# I94100_v1_3 register map
File version: 1.0
Registers are 32-bit, read-write, reset 0x0 unless marked. A register's access mark holds for its fields unless they carry their own. Offsets are from the block's base; [hi:lo] are bit positions; lines under a group give offsets from that group; {n}, {i} and the like mark numbered series; 'fields as' and 'values as' point back to an identical list.

## CLK — CLK Register Map
Base 0x40000200
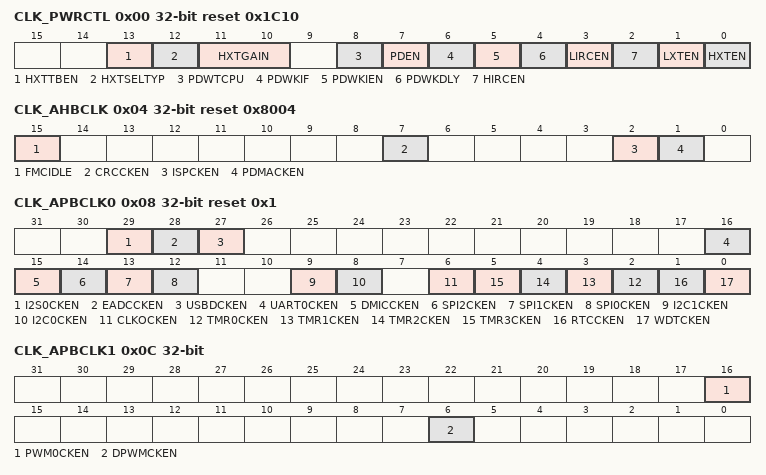
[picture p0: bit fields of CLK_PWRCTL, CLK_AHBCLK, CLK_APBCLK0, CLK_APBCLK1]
0x00 CLK_PWRCTL reset 0x1C10 (reset mask 0xFFFFFFF0) — System Power-down Control Register
  [13] HXTTBEN — HXT Crystal TURBO Mode (Write Protected). This is a protected register. Please refer to open lock sequence to program it.
    0=HXT Crystal TURBO mode disabled; 1=HXT Crystal TURBO mode enabled
  [12] HXTSELTYP — HXT Crystal Type Select Bit (Write Protected). This is a protected register. Please refer to open lock sequence to program it. Note: This bit is write protected. Refer to the SYS_REGLCTL register.
    0=Select INV type; 1=Select GM type
  [11:10] HXTGAIN — HXT Gain Control Bit (Write Protected). This is a protected register. Please refer to open lock sequence to program it. Gain control is used to enlarge the gain of crystal to make sure crystal work normally. If gain control is enabled, crystal will consume more power than gain control off. Note: This bit is write protected. Refer to the SYS_REGLCTL register.
    0=HXT frequency is lower than from 8 MHz; 1=HXT frequency is from 8 MHz to 12 MHz; 2=HXT frequency is from 12 MHz to 16 MHz; 3=HXT frequency is higher than 16 MHz
  [8] PDWTCPU — this Bit Control the Power-down Entry Condition (Write Protected). Note: This bit is write protected. Refer to the SYS_REGLCTL register.
    1=Chip enters Power-down mode when the both PDWTCPU and PDEN bits are set to 1 and CPU runs WFI instruction
  [7] PDEN — System Power-down Enable (Write Protected). When this bit is set to 1, Power-down mode is enabled and chip keeps active till the CPU sleep mode is also active and then the chip enters Power-down mode. When chip wakes up from Power-down mode, this bit is auto cleared. Users need to set this bit again for next Power-down. In Power-down mode, HXT and the HIRC will be disabled in this mode, but LXT and LIRC are not controlled by Power-down mode. In Power-down mode, the PLL and system clock are disabled, and ignored the clock source selection. The clocks of peripheral are not controlled by Power-down mode, if the peripheral clock source is from LXT or LIRC. Note: This bit is write protected. Refer to the SYS_REGLCTL register.
    0=Chip will not enter Power-down mode after CPU sleep command WFI; 1=Chip enters Power-down mode after CPU sleep command WFI
  [6] PDWKIF — Power-down Mode Wake-up Interrupt Status. Set by "Power-down wake-up event", it indicates that resume from Power-down mode" The flag is set if any wake-up source is occurred. Refer Power Modes and Wake-up Sources chapter. Note1: Write 1 to clear the bit to 0. Note2: This bit works only if PDWKIEN (CLK_PWRCTL[5]) set to 1.
  [5] PDWKIEN — Power-down Mode Wake-up Interrupt Enable Bit (Write Protected). Note1: The interrupt will occur when both PDWKIF and PDWKIEN are high. Note2: This bit is write protected. Refer to the SYS_REGLCTL register.
    0=Power-down mode wake-up interrupt Disabled; 1=Power-down mode wake-up interrupt Enabled
  [4] PDWKDLY — Enable the Wake-up Delay Counter (Write Protected). When the chip wakes up from Power-down mode, the clock control will delay certain clock cycles to wait system clock stable. The delayed clock cycle is 4096 clock cycles when chip works at external high speed crystal oscillator (HXT), and 128 clock cycles when chip works at internal high speed RC oscillator (HIRC). Note: This bit is write protected. Refer to the SYS_REGLCTL register.
    0=Clock cycles delay Disabled; 1=Clock cycles delay Enabled
  [3] LIRCEN — LIRC Enable Bit (Write Protected). Note 1: This bit is write protected. Refer to the SYS_REGLCTL register. Note 2: The reset value of this bit is 1. Note 3: The value of this bit must be kept 1.
    0=Internal low speed RC oscillator (LIRC) Disabled; 1=Internal low speed RC oscillator (LIRC) Enabled
  [2] HIRCEN — HIRC Enable Bit (Write Protected). Note 1: This bit is write protected. Refer to the SYS_REGLCTL register. Note 2: The reset value of this bit is 1.
    0=Internal high speed RC oscillator (HIRC) Disabled; 1=Internal high speed RC oscillator (HIRC) Enabled
  [1] LXTEN — LXT Enable Bit (Write Protected). Note 1: This bit is write protected. Refer to the SYS_REGLCTL register. Note 2: The reset value of this bit is 0.
    0=External low speed crystal (LXT) Disabled; 1=External low speed crystal (LXT) Enabled
  [0] HXTEN — HXT Enable Bit (Write Protected). The bit default value is set by flash controller user configuration register CONFIG0 [26]. When the default clock source is from HXT, this bit is set to 1 automatically. Note: This bit is write protected. Refer to the SYS_REGLCTL register.
    0=External high speed crystal (HXT) Disabled; 1=External high speed crystal (HXT) Enabled
0x04 CLK_AHBCLK reset 0x8004 — AHB Devices Clock Enable Control Register
  [15] FMCIDLE — Flash Memory Controller Clock Enable Bit in IDLE Mode
    0=FMC clock Disabled when chip is under IDLE mode; 1=FMC clock Enabled when chip is under IDLE mode
  [7] CRCCKEN — CRC Generator Controller Clock Enable Bit
    0=CRC peripheral clock Disabled; 1=CRC peripheral clock Enabled
  [2] ISPCKEN — Flash ISP Controller Clock Enable Bit
    0=Flash ISP peripheral clock Disabled; 1=Flash ISP peripheral clock Enabled
  [1] PDMACKEN — PDMA Controller Clock Enable Bit
    0=PDMA peripheral clock Disabled; 1=PDMA peripheral clock Enabled
0x08 CLK_APBCLK0 reset 0x1 — APB Devices Clock Enable Control Register 0
  [29] I2S0CKEN — I2S0 Clock Enable Bit
    0=I2S0 Clock Disabled; 1=I2S0 Clock Enabled
  [28] EADCCKEN — Enhanced Analog-digital-converter (EADC) Clock Enable Bit
    0=EADC clock Disabled; 1=EADC clock Enabled
  [27] USBDCKEN — USB Device Clock Enable Bit
    0=USB Device clock Disabled; 1=USB Device clock Enabled
  [16] UART0CKEN — UART0 Clock Enable Bit
    0=UART0 clock Disabled; 1=UART0 clock Enabled
  [15] DMICCKEN — DMIC Clock Enable Bit
    0=DMIC clock Disabled; 1=DMIC clock Enabled
  [14] SPI2CKEN — SPI2 Clock Enable Bit
    0=SPI2 clock Disabled; 1=SPI2 clock Enabled
  [13] SPI1CKEN — SPI1 Clock Enable Bit
    0=SPI1 clock Disabled; 1=SPI1 clock Enabled
  [12] SPI0CKEN — SPI0 Clock Enable Bit
    0=SPI0 clock Disabled; 1=SPI0 clock Enabled
  [9] I2C1CKEN — I2C1 Clock Enable Bit
    0=I2C1 clock Disabled; 1=I2C1 clock Enabled
  [8] I2C0CKEN — I2C0 Clock Enable Bit
    0=I2C0 clock Disabled; 1=I2C0 clock Enabled
  [6] CLKOCKEN — CLKO Clock Enable Bit
    0=CLKO clock Disabled; 1=CLKO clock Enabled
  [n+2] TMR{n}CKEN (n=0..3) — Timer{n} Clock Enable Bit
    0=Timer{n} clock Disabled; 1=Timer{n} clock Enabled
  [1] RTCCKEN — Real-time-clock APB Interface Clock Enable Bit. This bit is used to control the RTC APB clock only. The RTC peripheral clock source is selected from RTCSEL(CLK_CLKSEL3[8]). It can be selected to 32.768 kHz external low speed crystal or 10 kHz internal low speed RC oscillator (LIRC).
    0=RTC clock Disabled; 1=RTC clock Enabled
  [0] WDTCKEN — Watchdog Timer Clock Enable Bit (Write Protected). Note: This bit is write protected. Refer to the SYS_REGLCTL register.
    0=Watchdog timer clock Disabled; 1=Watchdog timer clock Enabled
0x0C CLK_APBCLK1 — APB Devices Clock Enable Control Register 1
  [16] PWM0CKEN — PWM0 Clock Enable Bit
    0=PWM0 clock Disabled; 1=PWM0 clock Enabled
  [6] DPWMCKEN — DPWM Clock Enable Bit
    0=DPWM clock Disabled; 1=DPWM clock Enabled
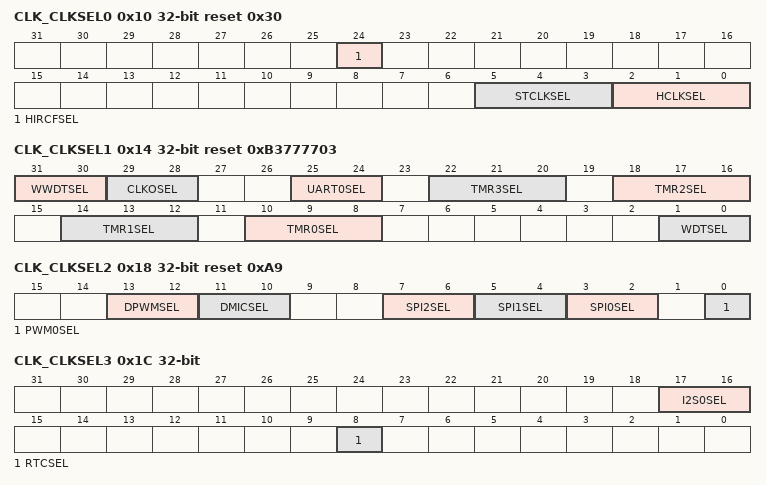
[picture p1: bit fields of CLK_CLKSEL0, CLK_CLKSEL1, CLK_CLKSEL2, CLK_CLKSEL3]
0x10 CLK_CLKSEL0 reset 0x30 (reset mask 0xFFFFFFF0) — Clock Source Select Control Register 0
  [24] HIRCFSEL — Internal High Speed RC Oscillator Frequency Selection. (Write Protect). Determines which trim setting to use for internal high speed RC oscillator. Note: This bit is write protected. Refer to the SYS_REGLCTL register.
    0=49.152 MHz; 1=48.0 MHz
  [5:3] STCLKSEL — Cortex®-M4 SysTick Clock Source Selection (Write Protected). Note2: The reset value of this field is 111b. Note3: This bit is write protected. Refer to the SYS_REGLCTL register.
    0=Clock source from HXT; 1=Clock source from LXT; 2=Clock source from HXT/2; 3=Clock source from HCLK/2; 7=Clock source from HIRC/2
  [2:0] HCLKSEL — HCLK Clock Source Selection (Write Protected). Before clock switching, the related clock sources (both pre-select and new-select) must be turned on and stable flag must be 1. The default value is reloaded from the value of CFOSC (CONFIG0[26]) in user configuration register of Flash controller by any reset. Therefore the default value is either 000b or 111b. Note: This bit is write protected. Refer to the SYS_REGLCTL register.
    0=Clock source from HXT; 1=Clock source from LXT; 2=Clock source from PLL; 3=Clock source from LIRC; 7=Clock source from HIRC
0x14 CLK_CLKSEL1 reset 0xB3777703 — Clock Source Select Control Register 1
  [31:30] WWDTSEL — Window Watchdog Timer Clock Source Selection
    2=Clock source from HCLK/2048; 3=Clock source from internal low speed RC oscillator (LIRC)
  [29:28] CLKOSEL — Clock Divider Clock Source Selection
    0=Clock source from external high speed crystal oscillator (HXT); 1=Clock source from external low speed crystal oscillator (LXT); 2=Clock source from HCLK; 3=Clock source from internal high speed RC oscillator (HIRC)
  [25:24] UART0SEL — UART0 Clock Source Selection
    0=Clock source from external high speed crystal oscillator (HXT); 1=Clock source from PLL; 2=Clock source from external low speed crystal oscillator (LXT); 3=Clock source from internal high speed RC oscillator (HIRC)
  [22:20] TMR3SEL — TIMER3 Clock Source Selection
    0=Clock source from external high speed crystal oscillator (HXT); 1=Clock source from external low speed crystal oscillator (LXT); 2=Clock source from PCLK1; 3=Clock source from external clock TM3 pin; 5=Clock source from internal low speed RC oscillator (LIRC); 7=Clock source from internal high speed RC oscillator (HIRC)
  [18:16] TMR2SEL — TIMER2 Clock Source Selection
    0=Clock source from external high speed crystal oscillator (HXT); 1=Clock source from external low speed crystal oscillator (LXT); 2=Clock source from PCLK1; 3=Clock source from external clock TM2 pin; 5=Clock source from internal low speed RC oscillator (LIRC); 7=Clock source from internal high speed RC oscillator (HIRC)
  [14:12] TMR1SEL — TIMER1 Clock Source Selection
    0=Clock source from external high speed crystal oscillator (HXT); 1=Clock source from external low speed crystal oscillator (LXT); 2=Clock source from PCLK0; 3=Clock source from external clock TM1 pin; 5=Clock source from internal low speed RC oscillator (LIRC); 7=Clock source from internal high speed RC oscillator (HIRC)
  [10:8] TMR0SEL — TIMER0 Clock Source Selection
    0=Clock source from external high speed crystal oscillator (HXT); 1=Clock source from external low speed crystal oscillator (LXT); 2=Clock source from PCLK0; 3=Clock source from external clock TM0 pin; 5=Clock source from internal low speed RC oscillator (LIRC); 7=Clock source from internal high speed RC oscillator (HIRC)
  [1:0] WDTSEL — Watchdog Timer Clock Source Selection (Write Protected). Note: This bit is write protected. Refer to the SYS_REGLCTL register.
    0=Reserved. Do not use; 1=Clock source from external low speed crystal oscillator (LXT); 2=Clock source from HCLK/2048; 3=Clock source from internal low speed RC oscillator (LIRC)
0x18 CLK_CLKSEL2 reset 0xA9 — Clock Source Select Control Register 2
  [13:12] DPWMSEL — DPWM Clock Source Selection
    0=Clock source from external high speed crystal oscillator (HXT); 1=Clock source from PLL; 2=Clock source from PCLK0; 3=Clock source from internal high speed RC oscillator (HIRC)
  [11:10] DMICSEL — DMIC Clock Source Selection
    0=Clock source from external high speed crystal oscillator (HXT); 1=Clock source from PLL; 2=Clock source from PCLK1; 3=Clock source from internal high speed RC oscillator (HIRC)
  [7:6] SPI2SEL — SPI2 Clock Source Selection
    values as DPWMSEL
  [5:4] SPI1SEL — SPI1 Clock Source Selection
    values as DMICSEL
  [3:2] SPI0SEL — SPI0 Clock Source Selection
    values as DPWMSEL
  [0] PWM0SEL — PWM0 Clock Source Selection. The peripheral clock source of PWM0 is defined by PWM0SEL.
    0=Clock source from PLL; 1=Clock source from PCLK0
0x1C CLK_CLKSEL3 — Clock Source Select Control Register 3
  [17:16] I2S0SEL — I2S0 Clock Source Selection
    0=Clock source from external high speed crystal oscillator (HXT); 1=Clock source from PLL clock; 2=Clock source from PCLK0; 3=Clock source from internal high speed RC oscillator (HIRC)
  [8] RTCSEL — RTC Clock Source Selection
    0=Clock source from external low speed crystal oscillator (LXT); 1=Clock source from internal low speed RC oscillator (LIRC)
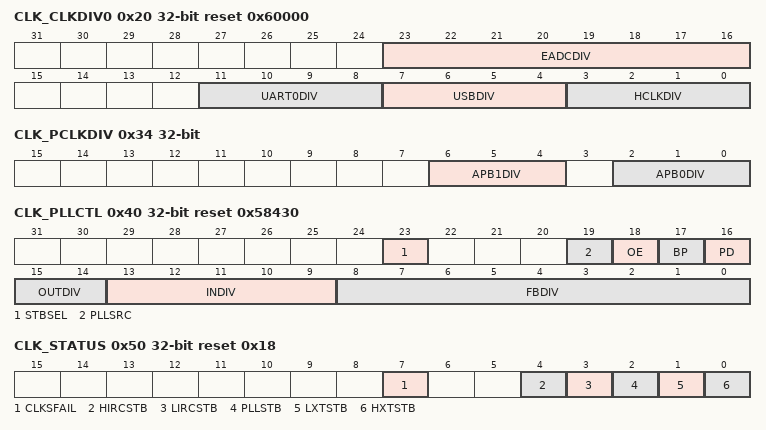
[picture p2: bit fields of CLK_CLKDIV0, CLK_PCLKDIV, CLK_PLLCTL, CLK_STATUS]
0x20 CLK_CLKDIV0 reset 0x60000 — Clock Divider Number Register 0
  [23:16] EADCDIV — EADC Clock Divide Number From EADC Clock Source
  [11:8] UART0DIV — UART0 Clock Divide Number From UART0 Clock Source
  [7:4] USBDIV — USB Clock Divide Number From PLL Clock
  [3:0] HCLKDIV — HCLK Clock Divide Number From HCLK Clock Source
0x24 CLK_CLKSEL4 — Clock Source Select Control Register 4
  [24] USBSEL — USB Clock Source Selection
    0=Clock source from internal high speed RC oscillator (HIRC); 1=Clock source from PLL
0x34 CLK_PCLKDIV — APB Clock Divider Register
  [6:4] APB1DIV — APB1 Clock Divider. APB1 clock can be divided from HCLK. Others: Reserved. Do not use. Note: When the clock rate of HCLK greater than 100 MHz, the value of APB1DIV (CLK_PCLKDIV[6:4]) and APB0DIV(CLK_PCLKDIV[2:0]) must be greater than 0.
  [2:0] APB0DIV — APB0 Clock Divider. APB0 clock can be divided from HCLK. Others: Reserved. Do not use. Note: When the clock rate of HCLK greater than 100 MHz, the value of APB1DIV (CLK_PCLKDIV[6:4]) and APB0DIV(CLK_PCLKDIV[2:0]) must be greater than 0.
0x40 CLK_PLLCTL reset 0x58430 — PLL Control Register
  [23] STBSEL — PLL Stable Counter Selection (Write Protected). Note: This bit is write protected. Refer to the SYS_REGLCTL register.
    0=PLL stable time is 6144 PLL source clock (suitable for source clock is equal to or less than 12 MHz); 1=PLL stable time is 12288 PLL source clock (suitable for source clock is larger than 12 MHz)
  [19] PLLSRC — PLL Source Clock Selection (Write Protected). Note: This bit is write protected. Refer to the SYS_REGLCTL register.
    0=PLL source clock from external high-speed crystal oscillator (HXT); 1=PLL source clock from internal high-speed oscillator (HIRC)
  [18] OE — PLL OE (FOUT Enable) Pin Control (Write Protected). Note: This bit is write protected. Refer to the SYS_REGLCTL register.
    0=PLL FOUT Enabled; 1=PLL FOUT is fixed low
  [17] BP — PLL Bypass Control (Write Protected). Note: This bit is write protected. Refer to the SYS_REGLCTL register.
    0=PLL is in normal mode (default); 1=PLL clock output is same as PLL input clock FIN
  [16] PD — Power-down Mode (Write Protected). If set the PDEN bit to 1 in CLK_PWRCTL register, the PLL will enter Power-down mode, too. Note: This bit is write protected. Refer to the SYS_REGLCTL register.
    0=PLL is in normal mode; 1=PLL is in Power-down mode (default)
  [15:14] OUTDIV — PLL Output Divider Control (Write Protected). Refer to the formulas below the table. Note: This bit is write protected. Refer to the SYS_REGLCTL register.
  [13:9] INDIV — PLL Input Divider Control (Write Protected). Refer to the formulas below the table. Note: This bit is write protected. Refer to the SYS_REGLCTL register.
  [8:0] FBDIV — PLL Feedback Divider Control (Write Protected). Refer to the formulas below the table. Note: This bit is write protected. Refer to the SYS_REGLCTL register.
0x50 CLK_STATUS ro reset 0x18 — Clock Status Monitor Register
  [7] CLKSFAIL — Clock Switching Fail Flag (Read Only). This bit is updated when software switches system clock source (CLK_CLKSEL0[2:0]). If switch target clock is stable, this bit will be set to 0. If switch target clock is not stable, this bit will be set to 1.
    0=Clock switching success; 1=Clock switching failure
  [4] HIRCSTB — HIRC Clock Source Stable Flag (Read Only)
    0=Internal high speed RC oscillator (HIRC) clock is not stable or disabled; 1=Internal high speed RC oscillator (HIRC) clock is stable and enabled
  [3] LIRCSTB — LIRC Clock Source Stable Flag (Read Only)
    0=Internal low speed RC oscillator (LIRC) clock is not stable or disabled; 1=Internal low speed RC oscillator (LIRC) clock is stable and enabled
  [2] PLLSTB — Internal PLL Clock Source Stable Flag (Read Only)
    0=Internal PLL clock is not stable or disabled; 1=Internal PLL clock is stable and enabled
  [1] LXTSTB — LXT Clock Source Stable Flag (Read Only)
    0=External low speed crystal oscillator (LXT) clock is not stable or disabled; 1=External low speed crystal oscillator (LXT) clock is stabled and enabled
  [0] HXTSTB — HXT Clock Source Stable Flag (Read Only)
    0=External high speed crystal oscillator (HXT) clock is not stable or disabled; 1=External high speed crystal oscillator (HXT) clock is stable and enabled
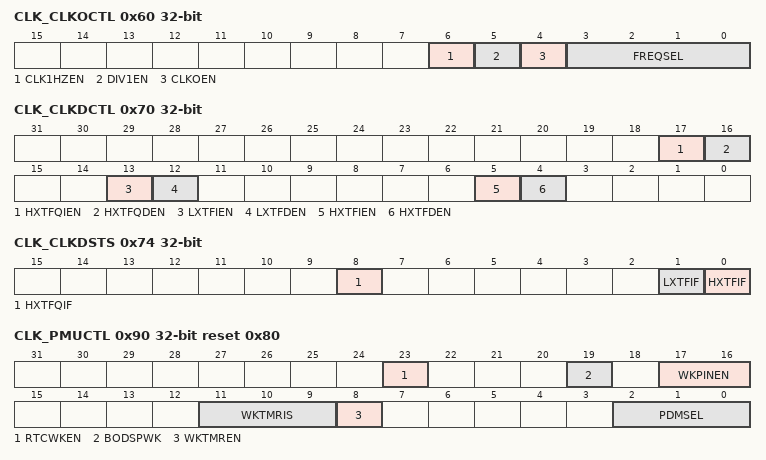
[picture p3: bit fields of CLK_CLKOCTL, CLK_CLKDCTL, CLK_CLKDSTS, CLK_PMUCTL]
0x60 CLK_CLKOCTL — Clock Output Control Register
  [6] CLK1HZEN — Clock Output 1Hz Enable Bit. Note: RTC IP need to be enabled.
    0=1 Hz clock output for RTC frequency compensation Disabled; 1=1 Hz clock output for RTC frequency compensation Enabled
  [5] DIV1EN — Clock Output Divide One Enable Bit
    0=Clock Output will output clock with source frequency divided by FREQSEL; 1=Clock Output will output clock with source frequency
  [4] CLKOEN — Clock Output Enable Bit
    0=Clock Output function Disabled; 1=Clock Output function Enabled
  [3:0] FREQSEL — Clock Output Frequency Selection. The formula of output frequency is. Fin is the input clock frequency. Fout is the frequency of divider output clock. N is the 4-bit value of FREQSEL[3:0].
0x70 CLK_CLKDCTL — Clock Fail Detector Control Register
  [17] HXTFQIEN — HXT Clock Frequency Range Detector Interrupt Enable Bit
    0=External high speed crystal oscillator (HXT) clock frequency Range Detector fail interrupt Disabled; 1=External high speed crystal oscillator (HXT) clock frequency Range Detector fail interrupt Enabled
  [16] HXTFQDEN — HXT Clock Frequency Monitor Enable Bit
    0=External high speed crystal oscillator (HXT) clock frequency Range Detector Disabled; 1=External high speed crystal oscillator (HXT) clock frequency Range Detector Enabled
  [13] LXTFIEN — LXT Clock Fail Interrupt Enable Bit
    0=External low speed crystal oscillator (LXT) clock fail interrupt Disabled; 1=External low speed crystal oscillator (LXT) clock fail interrupt Enabled
  [12] LXTFDEN — LXT Clock Fail Detector Enable Bit
    0=External low speed crystal oscillator (LXT) clock fail detector Disabled; 1=External low speed crystal oscillator (LXT) clock fail detector Enabled
  [5] HXTFIEN — HXT Clock Fail Interrupt Enable Bit
    0=External high speed crystal oscillator (HXT) clock fail interrupt Disabled; 1=External high speed crystal oscillator (HXT) clock fail interrupt Enabled
  [4] HXTFDEN — HXT Clock Fail Detector Enable Bit
    0=External high speed crystal oscillator (HXT) clock fail detector Disabled; 1=External high speed crystal oscillator (HXT) clock fail detector Enabled
0x74 CLK_CLKDSTS — Clock Fail Detector Status Register
  [8] HXTFQIF — HXT Clock Frequency Range Detector Interrupt Flag. Note: Write 1 to clear the bit to 0.
    0=External high speed crystal oscillator (HXT) clock frequency is normal; 1=External high speed crystal oscillator (HXT) clock frequency is abnormal
  [1] LXTFIF — LXT Clock Fail Interrupt Flag. Note: Write 1 to clear the bit to 0.
    0=External low speed crystal oscillator (LXT) clock is normal; 1=External low speed crystal oscillator (LXT) stops
  [0] HXTFIF — HXT Clock Fail Interrupt Flag. Note: Write 1 to clear the bit to 0.
    0=External high speed crystal oscillator (HXT) clock is normal; 1=External high speed crystal oscillator (HXT) clock stops
0x78 CLK_CDUPB — Clock Frequency Range Detector Upper Boundary Register
  [9:0] UPERBD — HXT Clock Frequency Range Detector Upper Boundary Value. The bits define the maximum value of frequency range detector window. The HXT detected frequency value is 512 * (the frequency of HXT / the frequency of HIRC). If the HXT detected frequency value higher than this maximum frequency value (UPERBD), the HXT Clock Frequency Range Detector Interrupt Flag (HXTFQIF(CLK_CLKDSTS[8])) will set to 1.
0x7C CLK_CDLOWB — Clock Frequency Range Detector Lower Boundary Register
  [9:0] LOWERBD — HXT Clock Frequency Range Detector Lower Boundary Value. The bits define the minimum value of frequency range detector window. The HXT detected frequency value is 512 * (the frequency of HXT / the frequency of HIRC). If the HXT detected frequency value lower than this minimum frequency value (LOWERBD), the HXT Clock Frequency Range Detector Interrupt Flag (HXTFQIF(CLK_CLKDSTS[8])) will set to 1.
0x90 CLK_PMUCTL reset 0x80 — Power Manager Control Register
  [23] RTCWKEN — RTC Wake-up Enable Bit (Write Protected). This is a protected register. Please refer to open lock sequence to program it. Note: This bit is write protected. Refer to the SYS_REGLCTL register.
    0=RTC wake-up disable at Standby Power-down mode; 1=RTC wake-up enabled at Standby Power-down mode
  [19] BODSPWK — BOD Standby Power-down Mode Wake-up Enable (Write Protected). This is a protected register. Please refer to open lock sequence to program it. Note: This bit is write protected. Refer to the SYS_REGLCTL register.
    0=BOD wake-up disable at Standby Power-down mode; 1=BOD wake-up enabled at Standby Power-down mode
  [17:16] WKPINEN — Wake-up Pin Enable (Write Protected). This is a protected register. Please refer to open lock sequence to program it. Note: This bit is write protected. Refer to the SYS_REGLCTL register.
    0=Wake-up pin disable at Deep Power-down mode; 1=Wake-up pin rising edge enabled at Deep Power-down mode; 2=Wake-up pin falling edge enabled at Deep Power-down mode; 3=Wake-up pin both edge enabled at Deep Power-down mode
  [11:9] WKTMRIS — Wake-up Timer Time-out Interval Select (Write Protected). This is a protected register. Please refer to open lock sequence to program it. These bits control wake-up timer time-out interval when chip at DPD/SPD mode. Note: This bit is write protected. Refer to the SYS_REGLCTL register.
    0=Time-out interval is 128 LIRC clocks (About 12.8 ms); 1=Time-out interval is 256 LIRC clocks (About 25.6 ms); 2=Time-out interval is 512 LIRC clocks (About 51.2 ms); 3=Time-out interval is 1024 LIRC clocks (About 102.4ms); 4=Time-out interval is 4096 LIRC clocks (About 409.6ms); 5=Time-out interval is 8192 LIRC clocks (About 819.2ms); 6=Time-out interval is 16384 LIRC clocks (About 1638.4ms); 7=Time-out interval is 65536 LIRC clocks (About 6553.6ms)
  [8] WKTMREN — Wake-up Timer Enable (Write Protected). This is a protected register. Please refer to open lock sequence to program it. Note: This bit is write protected. Refer to the SYS_REGLCTL register.
    0=Wake-up timer disable at DPD/SPD mode; 1=Wake-up timer enabled at DPD/SPD mode
  [2:0] PDMSEL — Power-down Mode Selection (Write Protected). This is a protected register. Please refer to open lock sequence to program it. These bits control chip power-down mode grade selection when CPU execute WFI/WFE instruction. Note: This bit is write protected. Refer to the SYS_REGLCTL register.
    0=Power-down mode is selected. (PD); 1=Low leakage Power-down mode is selected (LLPD); 2=Reserved. Do not use; 3=Reserved. Do not use; 4=Standby Power-down mode 0 is selected (SPD0) (SRAM retention); 5=Standby Power-down mode 1 is selected (SPD1); 6=Deep Power-down mode is selected (DPD); 7=Reserved. Do not use
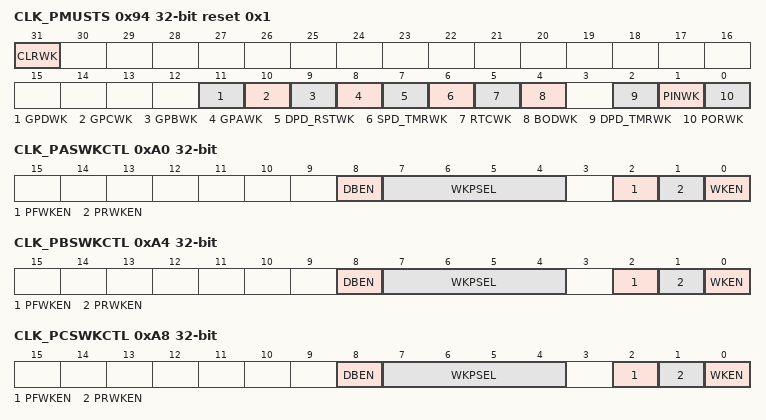
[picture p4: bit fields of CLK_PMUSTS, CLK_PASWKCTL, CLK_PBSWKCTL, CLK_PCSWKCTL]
0x94 CLK_PMUSTS reset 0x1 — Power Manager Status Register
  [31] CLRWK — Clear Wake-up Flag. Note: This bit is auto cleared by hardware.
    0=No clear; 1=Clear all wake-up flag
  [11] GPDWK ro — GPD Wake-up Flag (Read Only). This flag indicates that wake-up of chip from Standby Power-down mode was requested by a transition of selected one GPD group pins. This flag is cleared when SPD mode is entered.
  [10] GPCWK ro — GPC Wake-up Flag (Read Only). This flag indicates that wake-up of chip from Standby Power-down mode was requested by a transition of selected one GPC group pins. This flag is cleared when SPD mode is entered.
  [9] GPBWK ro — GPB Wake-up Flag (Read Only). This flag indicates that wake-up of chip from Standby Power-down mode was requested by a transition of selected one GPB group pins. This flag is cleared when SPD mode is entered.
  [8] GPAWK ro — GPA Wake-up Flag (Read Only). This flag indicates that wake-up of chip from Standby Power-down mode was requested by a transition of selected one GPA group pins. This flag is cleared when SPD mode is entered.
  [7] DPD_RSTWK ro — DPD Mode Reset Wake-up Flag (Read Only). This flag indicates that wakeup of device was requested with a reset. This flag is cleared when DPD mode is entered.
  [6] SPD_TMRWK ro — SPD Mode Wake-up Timer Wake-up Flag (Read Only). This flag indicates that wake-up of chip was requested by wakeup timer time-out. This flag is cleared when SPD mode is entered.
  [5] RTCWK ro — RTC Wake-up Flag (Read Only). This flag indicates that wakeup of device from Standby Power-down mode was requested with a RTC alarm or tick time happened. This flag is cleared when SPD mode is entered.
  [4] BODWK ro — BOD Wake-up Flag (Read Only). This flag indicates that wakeup of device from Standby Power-down mode was requested with a BOD happened. This flag is cleared when SPD mode is entered.
  [2] DPD_TMRWK ro — DPD Mode Wake-up Timer Wake-up Flag (Read Only). This flag indicates that wake-up of chip from Deep Power-down mode (DPD) was requested by wakeup timer time-out. This flag is cleared when DPD mode is entered.
  [1] PINWK ro — Pin Wake-up Flag (Read Only). This flag indicates that wake-up of chip from Deep Power-down mode was requested by a transition of the WAKEUP pin (PA.15). This flag is cleared when DPD mode is entered.
  [0] PORWK ro — Power-on-reset Wake-up Flag (Read Only). This flag indicates that wakeup of device was requested with a power-on reset. This flag is cleared when DPD mode is entered.
0x98 CLK_LDOCTL — Chip LDO Control Register
  [8] OVEN — LDO over Drive Enable Bit. Note: The bit must be set to 1 when the frequency of HCLK high than 160 MHz.
    0=LDO keep standard voltage operating; 1=LDO over drive voltage operating
0x9C CLK_SWKDBCTL — Standby Power-down Wake-up De-bounce Control Register
  [3:0] SWKDBCLKSEL — Standby Power-down Wake-up De-bounce Sampling Cycle Selection. Note: De-bounce counter clock source is the internal low speed RC oscillator (LIRC).
    0=Sample wake-up input once per 1 clocks; 1=Sample wake-up input once per 2 clocks; 2=Sample wake-up input once per 4 clocks; 3=Sample wake-up input once per 8 clocks; 4=Sample wake-up input once per 16 clocks; 5=Sample wake-up input once per 32 clocks; 6=Sample wake-up input once per 64 clocks; 7=Sample wake-up input once per 128 clocks; 8=Sample wake-up input once per 256 clocks; 9=Sample wake-up input once per 2*256 clocks; 10=Sample wake-up input once per 4*256 clocks; 11=Sample wake-up input once per 8*256 clocks; 12=Sample wake-up input once per 16*256 clocks; 13=Sample wake-up input once per 32*256 clocks; 14=Sample wake-up input once per 64*256 clocks; 15=Sample wake-up input once per 128*256 clocks
0xA0 CLK_PASWKCTL — GPA Standby Power-down Wakeup Control Register
  [8] DBEN — PA Input Signal De-bounce Enable Bit. The DBEN bit is used to enable the de-bounce function for each corresponding I/O. If the input signal pulse width cannot be sampled by continuous two de-bounce sample cycle, the input signal transition is seen as the signal bounce and will not trigger the wakeup. The de-bounce clock source is the internal low speed RC oscillator. The de-bounce function is valid only for edge triggered.
    0=Standby power-down wake-up pin De-bounce function disable; 1=Standby power-down wake-up pin De-bounce function enable
  [7:4] WKPSEL — PA Standby Power-down Wake-up Pin Select
    0=PA.0 wake-up function enabled; 1=PA.1 wake-up function enabled; 2=PA.2 wake-up function enabled; 3=PA.3 wake-up function enabled; 4=PA.4 wake-up function enabled; 5=PA.5 wake-up function enabled; 6=PA.6 wake-up function enabled; 7=PA.7 wake-up function enabled; 8=PA.8 wake-up function enabled; 9=PA.9 wake-up function enabled; 10=PA.10 wake-up function enabled; 11=PA.11 wake-up function enabled; 12=PA.12 wake-up function enabled; 13=PA.13 wake-up function enabled; 14=PA.14 wake-up function enabled; 15=PA.15 wake-up function enabled
  [2] PFWKEN — Pin Falling Edge Wake-up Enable Bit
    0=PA group pin falling edge wake-up function disabled; 1=PA group pin falling edge wake-up function enabled
  [1] PRWKEN — Pin Rising Edge Wake-up Enable Bit
    0=PA group pin rising edge wake-up function disabled; 1=PA group pin rising edge wake-up function enabled
  [0] WKEN — Standby Power-down Pin Wake-up Enable Bit
    0=PA group pin wake-up function disabled; 1=PA group pin wake-up function enabled
0xA4 CLK_PBSWKCTL — GPB Standby Power-down Wakeup Control Register
  [8] DBEN — PB Input Signal De-bounce Enable Bit. The DBEN bit is used to enable the de-bounce function for each corresponding I/O. If the input signal pulse width cannot be sampled by continuous two de-bounce sample cycle, the input signal transition is seen as the signal bounce and will not trigger the wakeup. The de-bounce clock source is the internal low speed RC oscillator. The de-bounce function is valid only for edge triggered.
    values as CLK_PASWKCTL.DBEN
  [7:4] WKPSEL — PB Standby Power-down Wake-up Pin Select
    0=PB.0 wake-up function enabled; 1=PB.1 wake-up function enabled; 2=PB.2 wake-up function enabled; 3=PB.3 wake-up function enabled; 4=PB.4 wake-up function enabled; 5=PB.5 wake-up function enabled; 6=PB.6 wake-up function enabled; 7=PB.7 wake-up function enabled; 8=PB.8 wake-up function enabled; 9=PB.9 wake-up function enabled; 10=Reserved. Do not use; 11=Reserved. Do not use; 12=Reserved. Do not use; 13=PB.13 wake-up function enabled; 14=PB.14 wake-up function enabled; 15=PB.15 wake-up function enabled
  [2] PFWKEN — Pin Falling Edge Wake-up Enable Bit
    0=PB group pin falling edge wake-up function disabled; 1=PB group pin falling edge wake-up function enabled
  [1] PRWKEN — Pin Rising Edge Wake-up Enable Bit
    0=PB group pin rising edge wake-up function disabled; 1=PB group pin rising edge wake-up function enabled
  [0] WKEN — Standby Power-down Pin Wake-up Enable Bit
    0=PB group pin wake-up function disabled; 1=PB group pin wake-up function enabled
0xA8 CLK_PCSWKCTL — GPC Standby Power-down Wakeup Control Register
  [8] DBEN — PC Input Signal De-bounce Enable Bit. The DBEN bit is used to enable the de-bounce function for each corresponding I/O. If the input signal pulse width cannot be sampled by continuous two de-bounce sample cycle, the input signal transition is seen as the signal bounce and will not trigger the wakeup. The de-bounce clock source is the internal low speed RC oscillator. The de-bounce function is valid only for edge triggered.
    values as CLK_PASWKCTL.DBEN
  [7:4] WKPSEL — PC Standby Power-down Wake-up Pin Select
    0=PC.0 wake-up function enabled; 1=PC.1 wake-up function enabled; 2=PC.2 wake-up function enabled; 3=PC.3 wake-up function enabled; 4=PC.4 wake-up function enabled; 5=PC.5 wake-up function enabled; 6=PC.6 wake-up function enabled; 7=PC.7 wake-up function enabled; 8=PC.8 wake-up function enabled; 9=PC.9 wake-up function enabled; 10=PC.10 wake-up function enabled; 11=PC.11 wake-up function enabled; 12=PC.12 wake-up function enabled; 13=PC.13 wake-up function enabled; 14=PC.14 wake-up function enabled; 15=PC.15 wake-up function enabled
  [2] PFWKEN — Pin Falling Edge Wake-up Enable Bit
    0=PC group pin falling edge wake-up function disabled; 1=PC group pin falling edge wake-up function enabled
  [1] PRWKEN — Pin Rising Edge Wake-up Enable Bit
    0=PC group pin rising edge wake-up function disabled; 1=PC group pin rising edge wake-up function enabled
  [0] WKEN — Standby Power-down Pin Wake-up Enable Bit
    0=PC group pin wake-up function disabled; 1=PC group pin wake-up function enabled
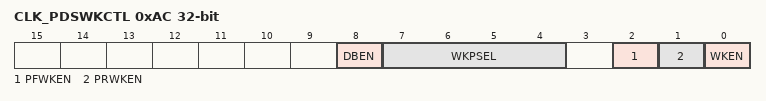
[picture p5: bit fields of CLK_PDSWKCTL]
0xAC CLK_PDSWKCTL — GPD Standby Power-down Wakeup Control Register
  [8] DBEN — PD Input Signal De-bounce Enable Bit. The DBEN bit is used to enable the de-bounce function for each corresponding I/O. If the input signal pulse width cannot be sampled by continuous two de-bounce sample cycle, the input signal transition is seen as the signal bounce and will not trigger the wakeup. The de-bounce clock source is the internal low speed RC oscillator. The de-bounce function is valid only for edge triggered.
    values as CLK_PASWKCTL.DBEN
  [7:4] WKPSEL — PD Standby Power-down Wake-up Pin Select
    0=PD.0 wake-up function enabled; 1=PD.1 wake-up function enabled; 2=PD.2 wake-up function enabled; 3=PD.3 wake-up function enabled; 4=PD.4 wake-up function enabled; 5=PD.5 wake-up function enabled; 6=PD.6 wake-up function enabled; 7=PD.7 wake-up function enabled; 8=PD.8 wake-up function enabled; 9=PD.9 wake-up function enabled; 10=PD.10 wake-up function enabled; 11=PD.11 wake-up function enabled; 12=PD.12 wake-up function enabled; 13=PD.13 wake-up function enabled; 14=PD.14 wake-up function enabled; 15=PD.15 wake-up function enabled
  [2] PFWKEN — Pin Falling Edge Wake-up Enable Bit
    0=PD group pin falling edge wake-up function disabled; 1=PD group pin falling edge wake-up function enabled
  [1] PRWKEN — Pin Rising Edge Wake-up Enable Bit
    0=PD group pin rising edge wake-up function disabled; 1=PD group pin rising edge wake-up function enabled
  [0] WKEN — Standby Power-down Pin Wake-up Enable Bit
    0=PD group pin wake-up function disabled; 1=PD group pin wake-up function enabled
0xB0 CLK_IOPDCTL — GPIO Standby Power-down Control Register
  [0] IOHR — GPIO Hold Release. When GPIO enter standby power-down mode, all I/O status are hold to keep normal operating status. After chip was waked up from standby power-down mode, the I/O are still keep hold status until user set this bit to release I/O hold status. This bit is auto cleared by hardware.
